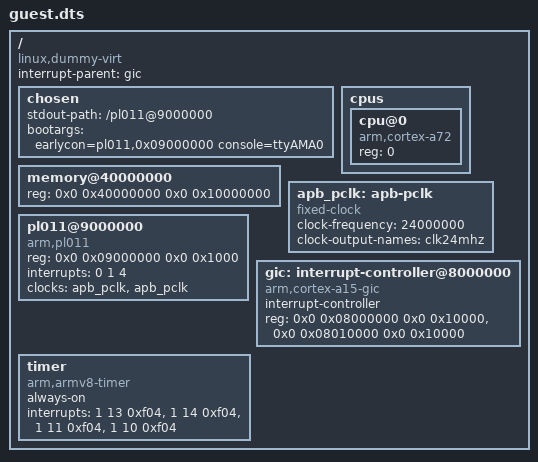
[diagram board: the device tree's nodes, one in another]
/dts-v1/;

/ {
	compatible = "linux,dummy-virt";
	#address-cells = <2>;
	#size-cells = <2>;
	interrupt-parent = <&gic>;

	chosen {
		stdout-path = "/pl011@9000000";
		bootargs = "earlycon=pl011,0x09000000 console=ttyAMA0";
	};

	memory@40000000 {
		device_type = "memory";
		reg = <0x0 0x40000000 0x0 0x10000000>;
	};

	cpus {
		#address-cells = <1>;
		#size-cells = <0>;

		cpu@0 {
			device_type = "cpu";
			compatible = "arm,cortex-a72";
			reg = <0>;
		};
	};

	apb_pclk: apb-pclk {
		compatible = "fixed-clock";
		#clock-cells = <0>;
		clock-frequency = <24000000>;
		clock-output-names = "clk24mhz";
	};

	pl011@9000000 {
		compatible = "arm,pl011", "arm,primecell";
		reg = <0x0 0x09000000 0x0 0x1000>;
		interrupts = <0 1 4>;
		clocks = <&apb_pclk>, <&apb_pclk>;
		clock-names = "uartclk", "apb_pclk";
	};

	gic: interrupt-controller@8000000 {
		compatible = "arm,cortex-a15-gic";
		#interrupt-cells = <3>;
		interrupt-controller;
		reg = <0x0 0x08000000 0x0 0x10000>,
		      <0x0 0x08010000 0x0 0x10000>;
	};

	timer {
		compatible = "arm,armv8-timer";
		always-on;
		interrupts = <1 13 0xf04>,
		             <1 14 0xf04>,
		             <1 11 0xf04>,
		             <1 10 0xf04>;
	};
};
